AUTOSAR XML (schema 4-2-2)
package /ComponentTypes
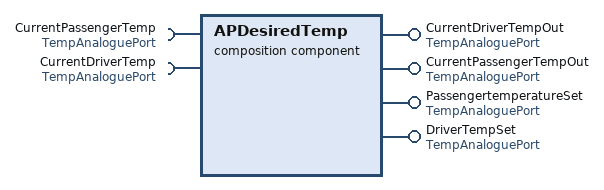
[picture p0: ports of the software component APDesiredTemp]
  composition sw component type APDesiredTemp
    require port CurrentPassengerTemp: required-interface=TempAnaloguePort
    require port CurrentDriverTemp: required-interface=TempAnaloguePort
    4 x provide port, all with provided-interface=TempAnaloguePort:
      CurrentDriverTempOut
      CurrentPassengerTempOut
      PassengertemperatureSet
      DriverTempSet
    component CabinTempClosedLoop: type=CabinTempClosedLoop
    delegate CabinTempClosedLoop.currentTempSet <-> outer port CurrentPassengerTemp
    delegate CabinTempClosedLoop.currentTempSet <-> outer port CurrentDriverTemp
    delegate CabinTempClosedLoop.currentTempSet <-> outer port CurrentDriverTempOut
    delegate CabinTempClosedLoop.currentTempSet <-> outer port CurrentPassengerTempOut
    delegate CabinTempClosedLoop.currentTempSet <-> outer port DriverTempSet
    delegate CabinTempClosedLoop.currentTempSet <-> outer port PassengertemperatureSet
